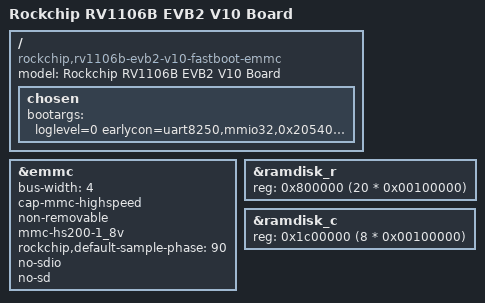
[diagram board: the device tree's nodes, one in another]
// SPDX-License-Identifier: (GPL-2.0+ OR MIT)
/*
 * Copyright (c) 2026 Rockchip Electronics Co., Ltd.
 */

/dts-v1/;

#include "rv1106b.dtsi"
#include "rv1106b-evb2-v10.dtsi"
#include "rv1106b-evb2-cam.dtsi"
#include "rv1106b-fastboot-emmc.dtsi"

/ {
	model = "Rockchip RV1106B EVB2 V10 Board";
	compatible = "rockchip,rv1106b-evb2-v10-fastboot-emmc", "rockchip,rv1106b";

	chosen {
		bootargs = "loglevel=0 earlycon=uart8250,mmio32,0x20540000 console=ttyFIQ0 root=/dev/rd0 rootfstype=erofs rootflags=dax snd_soc_core.prealloc_buffer_size_kbytes=16 coherent_pool=32K";
	};
};

&emmc {
	bus-width = <4>;
	cap-mmc-highspeed;
	non-removable;
	mmc-hs200-1_8v;
	rockchip,default-sample-phase = <90>;
	no-sdio;
	no-sd;
	status = "okay";
};

&ramdisk_r {
	reg = <0x800000 (20 * 0x00100000)>;
};

&ramdisk_c {
	reg = <0x1c00000 (8 * 0x00100000)>;
};
